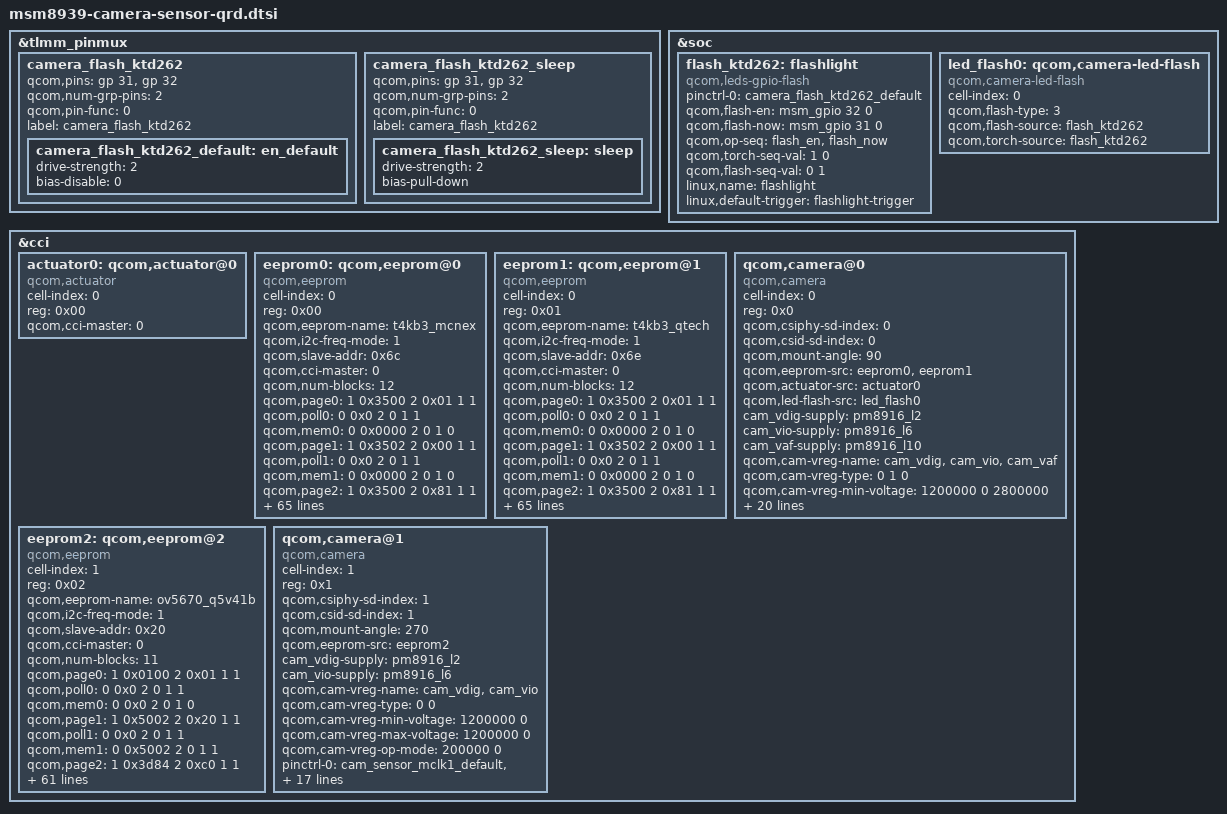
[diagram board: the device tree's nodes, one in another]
/*
 * Copyright (c) 2014, The Linux Foundation. All rights reserved.
 *
 * This program is free software; you can redistribute it and/or modify
 * it under the terms of the GNU General Public License version 2 and
 * only version 2 as published by the Free Software Foundation.
 *
 * This program is distributed in the hope that it will be useful,
 * but WITHOUT ANY WARRANTY; without even the implied warranty of
 * MERCHANTABILITY or FITNESS FOR A PARTICULAR PURPOSE.  See the
 * GNU General Public License for more details.
 */


&tlmm_pinmux {
	camera_flash_ktd262 {
		qcom,pins = <&gp 31>, <&gp 32>;
		qcom,num-grp-pins = <2>;
		qcom,pin-func = <0>;
		label = "camera_flash_ktd262";
		camera_flash_ktd262_default: en_default {
			  drive-strength = <2>;
			  bias-disable = <0>;
		};
	};
	
	camera_flash_ktd262_sleep {
		/* FLSH_RESET,FLASH_EN,FLASH_NOW */
		qcom,pins = <&gp 31>,<&gp 32> ;
		qcom,num-grp-pins = <2>;
		qcom,pin-func = <0>;
		label = "camera_flash_ktd262";
		/* active state */
		camera_flash_ktd262_sleep: sleep {
			drive-strength = <2>; /* 2 MA */
			bias-pull-down; /* PULL DOWN */
		};
	};	
};

&soc {
	flash_ktd262:flashlight {
		compatible = "qcom,leds-gpio-flash";
		status = "okay";
		pinctrl-names = "camera_flash_ktd262_default";
		pinctrl-0 = <&camera_flash_ktd262_default>;
		qcom,flash-en = <&msm_gpio 32 0>;
		qcom,flash-now = <&msm_gpio 31 0>;
		qcom,op-seq = "flash_en", "flash_now";
		qcom,torch-seq-val = <1 0>;
		qcom,flash-seq-val = <0 1>;
		linux,name = "flashlight";
		linux,default-trigger = "flashlight-trigger";
	};

	led_flash0: qcom,camera-led-flash {
		cell-index = <0>;
		compatible = "qcom,camera-led-flash";
		qcom,flash-type = <3>;
		qcom,flash-source = <&flash_ktd262>;
		qcom,torch-source = <&flash_ktd262>;
	};
};

&cci {
	actuator0: qcom,actuator@0 {
		cell-index = <0>;
		reg = <0x00>;
		compatible = "qcom,actuator";
		qcom,cci-master = <0>;
	};

	eeprom0: qcom,eeprom@0 {
		cell-index = <0>;
		reg = <0x00>;
		qcom,eeprom-name = "t4kb3_mcnex";
		compatible = "qcom,eeprom";
		qcom,i2c-freq-mode = <1>;
		qcom,slave-addr = <0x6c>;
		qcom,cci-master = <0>;
		qcom,num-blocks = <12>;

		qcom,page0 = <1 0x3500 2 0x01 1 1>;
		qcom,poll0 = <0 0x0 2 0 1 1>;
		qcom,mem0 = <0 0x0000 2 0 1 0>;

		qcom,page1 = <1 0x3502 2 0x00 1 1>;
		qcom,poll1 = <0 0x0 2 0 1 1>;
		qcom,mem1 = <0 0x0000 2 0 1 0>;

		qcom,page2 = <1 0x3500 2 0x81 1 1>;
		qcom,poll2 = <0 0x0 2 0 1 1>;
		qcom,mem2 = <64 0x3504 2 0 1 0>;

		qcom,page3 = <1 0x3500 2 0x00 1 1>;
		qcom,poll3 = <0 0x0 2 0 1 1>;
		qcom,mem3 = <0 0x0000 2 0 1 0>;

		qcom,page4 = <1 0x3500 2 0x01 1 1>;
		qcom,poll4 = <0 0x0 2 0 1 1>;
		qcom,mem4 = <0 0x0000 2 0 1 0>;

		qcom,page5 = <1 0x3502 2 0x01 1 1>;
		qcom,poll5 = <0 0x0 2 0 1 1>;
		qcom,mem5 = <0 0x0000 2 0 1 0>;

		qcom,page6 = <1 0x3500 2 0x81 1 1>;
		qcom,poll6 = <0 0x0 2 0 1 1>;
		qcom,mem6 = <64 0x3504 2 0 1 0>;

		qcom,page7 = <1 0x3500 2 0x00 1 1>;
		qcom,poll7 = <0 0x0 2 0 1 1>;
		qcom,mem7 = <0 0x0000 2 0 1 0>;

		qcom,page8 = <1 0x3500 2 0x01 1 1>;
		qcom,poll8 = <0 0x0 2 0 1 1>;
		qcom,mem8 = <0 0x0000 2 0 1 0>;
		
		qcom,page9 = <1 0x3502 2 0x02 1 1>;
		qcom,poll9 = <0 0x0 2 0 1 1>;
		qcom,mem9 = <0 0x0000 2 0 1 0>;

		qcom,page10 = <1 0x3500 2 0x81 1 1>;
		qcom,poll10 = <0 0x0 2 0 1 1>;
		qcom,mem10 = <64 0x3504 2 0 1 0>;

		qcom,page11 = <1 0x3500 2 0x00 1 1>;
		qcom,poll11 = <0 0x0 2 0 1 1>;
		qcom,mem11 = <0 0x0000 2 0 1 0>;

		cam_vdig-supply = <&pm8916_l2>;
		cam_vio-supply = <&pm8916_l6>;
		cam_vaf-supply = <&pm8916_l10>;
		qcom,cam-vreg-name = "cam_vdig", "cam_vio","cam_vaf";
		qcom,cam-vreg-type = <0 0 0>;
		qcom,cam-vreg-min-voltage = <1200000 1800000 2800000>;
		qcom,cam-vreg-max-voltage = <1200000 1800000 2800000>;
		qcom,cam-vreg-op-mode = <200000 100000 100000>;
		pinctrl-names = "cam_default", "cam_suspend";
		pinctrl-0 = <&cam_sensor_mclk0_default &cam_sensor_rear_default>;
		pinctrl-1 = <&cam_sensor_mclk0_sleep &cam_sensor_rear_sleep>;
		gpios = <&msm_gpio 26 0>,
			<&msm_gpio 35 0>,
			<&msm_gpio 34 0>,
			<&msm_gpio 2 0>;
		qcom,gpio-reset = <1>;
		qcom,gpio-standby = <2>;
		qcom,gpio-vana = <3>;
		qcom,gpio-req-tbl-num = <0 1 2 3>;
		qcom,gpio-req-tbl-flags = <1 0 0 0>;
		qcom,gpio-req-tbl-label = "CAMIF_MCLK0",
			"MCAM_RESET",
			"MCAM_STANDBY",
			"MCAM_AVDD_EN";
		qcom,cam-power-seq-type = "sensor_vreg", "sensor_gpio", "sensor_gpio", "sensor_vreg",
				"sensor_vreg", "sensor_gpio", "sensor_gpio",
		        "sensor_clk", "sensor_i2c_mux";
		qcom,cam-power-seq-val = "cam_vdig", "sensor_gpio_vana","sensor_gpio_vana","cam_vio",
		                                          "cam_vaf","sensor_gpio_reset", "sensor_gpio_reset", 
		                                           "sensor_cam_mclk", "none";
		qcom,cam-power-seq-cfg-val = <1 0 1 1 1 0 1 24000000 0>;
		qcom,cam-power-seq-delay =    <1 1 1 1 5 5 30 1  0>;
		status = "ok";
		clocks = <&clock_gcc clk_mclk0_clk_src>,
				<&clock_gcc clk_gcc_camss_mclk0_clk>;
		clock-names = "cam_src_clk", "cam_clk";
	};

	eeprom1: qcom,eeprom@1 {
		cell-index = <0>;
		reg = <0x01>;
		qcom,eeprom-name = "t4kb3_qtech";
		compatible = "qcom,eeprom";
		qcom,i2c-freq-mode = <1>;
		qcom,slave-addr = <0x6e>;
		qcom,cci-master = <0>;
		qcom,num-blocks = <12>;

		qcom,page0 = <1 0x3500 2 0x01 1 1>;
		qcom,poll0 = <0 0x0 2 0 1 1>;
		qcom,mem0 = <0 0x0000 2 0 1 0>;

		qcom,page1 = <1 0x3502 2 0x00 1 1>;
		qcom,poll1 = <0 0x0 2 0 1 1>;
		qcom,mem1 = <0 0x0000 2 0 1 0>;

		qcom,page2 = <1 0x3500 2 0x81 1 1>;
		qcom,poll2 = <0 0x0 2 0 1 1>;
		qcom,mem2 = <64 0x3504 2 0 1 0>;

		qcom,page3 = <1 0x3500 2 0x00 1 1>;
		qcom,poll3 = <0 0x0 2 0 1 1>;
		qcom,mem3 = <0 0x0000 2 0 1 0>;

		qcom,page4 = <1 0x3500 2 0x01 1 1>;
		qcom,poll4 = <0 0x0 2 0 1 1>;
		qcom,mem4 = <0 0x0000 2 0 1 0>;

		qcom,page5 = <1 0x3502 2 0x01 1 1>;
		qcom,poll5 = <0 0x0 2 0 1 1>;
		qcom,mem5 = <0 0x0000 2 0 1 0>;

		qcom,page6 = <1 0x3500 2 0x81 1 1>;
		qcom,poll6 = <0 0x0 2 0 1 1>;
		qcom,mem6 = <64 0x3504 2 0 1 0>;

		qcom,page7 = <1 0x3500 2 0x00 1 1>;
		qcom,poll7 = <0 0x0 2 0 1 1>;
		qcom,mem7 = <0 0x0000 2 0 1 0>;

		qcom,page8 = <1 0x3500 2 0x01 1 1>;
		qcom,poll8 = <0 0x0 2 0 1 1>;
		qcom,mem8 = <0 0x0000 2 0 1 0>;
		
		qcom,page9 = <1 0x3502 2 0x02 1 1>;
		qcom,poll9 = <0 0x0 2 0 1 1>;
		qcom,mem9 = <0 0x0000 2 0 1 0>;

		qcom,page10 = <1 0x3500 2 0x81 1 1>;
		qcom,poll10 = <0 0x0 2 0 1 1>;
		qcom,mem10 = <64 0x3504 2 0 1 0>;

		qcom,page11 = <1 0x3500 2 0x00 1 1>;
		qcom,poll11 = <0 0x0 2 0 1 1>;
		qcom,mem11 = <0 0x0000 2 0 1 0>;

		cam_vdig-supply = <&pm8916_l2>;
		cam_vio-supply = <&pm8916_l6>;
		cam_vaf-supply = <&pm8916_l10>;
		qcom,cam-vreg-name = "cam_vdig", "cam_vio","cam_vaf";
		qcom,cam-vreg-type = <0 0 0>;
		qcom,cam-vreg-min-voltage = <1200000 1800000 2800000>;
		qcom,cam-vreg-max-voltage = <1200000 1800000 2800000>;
		qcom,cam-vreg-op-mode = <200000 100000 100000>;
		pinctrl-names = "cam_default", "cam_suspend";
		pinctrl-0 = <&cam_sensor_mclk0_default &cam_sensor_rear_default>;
		pinctrl-1 = <&cam_sensor_mclk0_sleep &cam_sensor_rear_sleep>;
		gpios = <&msm_gpio 26 0>,
			<&msm_gpio 35 0>,
			<&msm_gpio 34 0>,
			<&msm_gpio 2 0>;
		qcom,gpio-reset = <1>;
		qcom,gpio-standby = <2>;
		qcom,gpio-vana = <3>;
		qcom,gpio-req-tbl-num = <0 1 2 3>;
		qcom,gpio-req-tbl-flags = <1 0 0 0>;
		qcom,gpio-req-tbl-label = "CAMIF_MCLK0",
			"MCAM_RESET",
			"MCAM_STANDBY",
			"MCAM_AVDD_EN";
		qcom,cam-power-seq-type = "sensor_vreg", "sensor_gpio", "sensor_gpio", "sensor_vreg",
				"sensor_vreg", "sensor_gpio", "sensor_gpio",
		        "sensor_clk", "sensor_i2c_mux";
		qcom,cam-power-seq-val = "cam_vdig", "sensor_gpio_vana","sensor_gpio_vana","cam_vio",
		                                          "cam_vaf","sensor_gpio_reset", "sensor_gpio_reset", 
		                                           "sensor_cam_mclk", "none";
		qcom,cam-power-seq-cfg-val = <1 0 1 1 1 0 1 24000000 0>;
		qcom,cam-power-seq-delay =    <1 1 1 1 5 5 30 1  0>;
		status = "ok";
		clocks = <&clock_gcc clk_mclk0_clk_src>,
				<&clock_gcc clk_gcc_camss_mclk0_clk>;
		clock-names = "cam_src_clk", "cam_clk";
	};

	qcom,camera@0 {
		cell-index = <0>;
		compatible = "qcom,camera";
		reg = <0x0>;
		qcom,csiphy-sd-index = <0>;
		qcom,csid-sd-index = <0>;
		qcom,mount-angle = <90>;
		qcom,eeprom-src = <&eeprom0 &eeprom1>;
		qcom,actuator-src = <&actuator0>;
		qcom,led-flash-src = <&led_flash0>;
		cam_vdig-supply = <&pm8916_l2>;
		/*cam_vana-supply = <&pm8916_l17>;*/
		cam_vio-supply = <&pm8916_l6>;
		cam_vaf-supply = <&pm8916_l10>;
		qcom,cam-vreg-name = "cam_vdig", "cam_vio","cam_vaf";
		qcom,cam-vreg-type = <0 1 0>;
		qcom,cam-vreg-min-voltage = <1200000 0 2800000>;
		qcom,cam-vreg-max-voltage = <1200000 0 2800000>;
		qcom,cam-vreg-op-mode = <200000 0 100000>;
		pinctrl-names = "cam_default", "cam_suspend";
		pinctrl-0 = <&cam_sensor_mclk0_default &cam_sensor_rear_default>;
		pinctrl-1 = <&cam_sensor_mclk0_sleep &cam_sensor_rear_sleep>;
		gpios = <&msm_gpio 26 0>,
			<&msm_gpio 35 0>,
			<&msm_gpio 34 0>,
			<&msm_gpio 2 0>;
		qcom,gpio-reset = <1>;
		qcom,gpio-standby = <2>;
		qcom,gpio-vana = <3>;
		qcom,gpio-req-tbl-num = <0 1 2 3>;
		qcom,gpio-req-tbl-flags = <1 0 0 0>;
		qcom,gpio-req-tbl-label = "CAMIF_MCLK0",
			"MCAM_RESET",
			"MCAM_STANDBY",
			"MCAM_AVDD_EN";
		qcom,sensor-position = <0>;
		qcom,sensor-mode = <0>;
		qcom,cci-master = <0>;
		status = "ok";
		clocks = <&clock_gcc clk_mclk0_clk_src>,
				<&clock_gcc clk_gcc_camss_mclk0_clk>;
		clock-names = "cam_src_clk", "cam_clk";
	};

	eeprom2: qcom,eeprom@2 {
		cell-index = <1>;
		reg = <0x02>;
		qcom,eeprom-name = "ov5670_q5v41b";
		compatible = "qcom,eeprom";
		qcom,i2c-freq-mode = <1>;
		qcom,slave-addr = <0x20>;
		qcom,cci-master = <0>;
		qcom,num-blocks = <11>;
        	qcom,page0 = <1 0x0100 2 0x01 1 1>;
        	qcom,poll0 = <0 0x0 2 0 1 1>;
        	qcom,mem0 = <0 0x0 2 0 1 0>;
		qcom,page1 = <1 0x5002 2 0x20 1 1>;
		qcom,poll1 = <0 0x0 2 0 1 1>;
		qcom,mem1 = <0 0x5002 2 0 1 1>;
		qcom,page2 = <1 0x3d84 2 0xc0 1 1>;
		qcom,poll2 = <0 0x0 2 0 1 1>;
		qcom,mem2 = <0 0x3d84 2 0 1 0>;
		qcom,page3 = <1 0x3d88 2 0x70 1 1>;
		qcom,poll3 = <0 0x0 2 0 1 1>;
		qcom,mem3 = <0 0x3d88 2 0 1 0>;
		qcom,page4 = <1 0x3d89 2 0x10 1 1>;
		qcom,poll4 = <0 0x0 2 0 1 1>;
		qcom,mem4 = <0 0x3d89 2 0 1 0>;
		qcom,page5 = <1 0x3d8a 2 0x70 1 1>;
		qcom,poll5 = <0 0x0 2 0 1 1>;
		qcom,mem5 = <0 0x3d8a 2 0 1 0>;
		qcom,page6 = <1 0x3d8b 2 0x29 1 1>;
		qcom,poll6 = <0 0x0 2 0 1 1>;
		qcom,mem6 = <0 0x3d8b 2 0 1 0>;
		qcom,page7 = <1 0x3d81 2 0x01 1 5>;
		qcom,poll7 = <0 0x0 2 0 1 1>;
		qcom,mem7 = <0 0x3d81 2 0 1 0>;
		qcom,page8 = <0 0x00 1 0x01 1 1>;
		qcom,poll8 = <0 0x0 2 0 1 1>;
		qcom,mem8= <26 0x7010 2 0 1 1>;//read OTP flag
		qcom,page9 = <1 0x5002 2 0x28 1 1>;
		qcom,poll9 = <0 0x0 2 0 1 1>;
		qcom,mem9= <0 0x7020 2 0 1 0>;
		qcom,page10 = <1 0x0100 2 0x00 1 1>;
		qcom,poll10 = <0 0x0 2 0 1 1>;
		qcom,mem10= <0 0x7020 2 0 1 0>;
		
		cam_vdig-supply = <&pm8916_l2>;
		cam_vio-supply = <&pm8916_l6>;
		qcom,cam-vreg-name = "cam_vdig", "cam_vio";
		qcom,cam-vreg-type = <0 0>;
		qcom,cam-vreg-min-voltage = <1200000 1800000>;
		qcom,cam-vreg-max-voltage = <1200000 1800000>;
		qcom,cam-vreg-op-mode = <150000 150000>;
		pinctrl-names = "cam_default", "cam_suspend";
		pinctrl-0 = <&cam_sensor_mclk1_default &cam_sensor_front_default>;
		pinctrl-1 = <&cam_sensor_mclk1_sleep &cam_sensor_front_sleep>;
		gpios = <&msm_gpio 27 0>,
			<&msm_gpio 28 0>,
			<&msm_gpio 33 0>,
			<&msm_gpio 2  0>;
		qcom,gpio-reset = <1>;
		qcom,gpio-standby = <2>;
		qcom,gpio-vana = <3>;
		qcom,gpio-req-tbl-num = <0 1 2 3>;
		qcom,gpio-req-tbl-flags = <1 0 0 0>;
		qcom,gpio-req-tbl-label = "CAMIF_MCLK1",
			"SCAM_RESET",
			"SCAM_STANDBY",
			"SCAM_AVDD_EN";
		qcom,cam-power-seq-type = "sensor_vreg", "sensor_gpio", "sensor_gpio",
		               "sensor_vreg", "sensor_gpio", "sensor_gpio",
				"sensor_gpio", "sensor_gpio", "sensor_clk", "sensor_i2c_mux";
		qcom,cam-power-seq-val = "cam_vio", "sensor_gpio_vana", "sensor_gpio_vana", 
		              "cam_vdig", "sensor_gpio_standby","sensor_gpio_standby",
 				 "sensor_gpio_reset","sensor_gpio_reset", "sensor_cam_mclk",
		                "none";
		qcom,cam-power-seq-cfg-val = <1 0 1 1 0 1 0 1   24000000 0>;
		qcom,cam-power-seq-delay =   <1  1 1 1 1 5 5 30 10  0>;
		status = "ok";
		clocks = <&clock_gcc clk_mclk1_clk_src>,
				<&clock_gcc clk_gcc_camss_mclk1_clk>;
		clock-names = "cam_src_clk", "cam_clk";
	};

	qcom,camera@1 {
		cell-index = <1>;
		compatible = "qcom,camera";
		reg = <0x1>;
		qcom,csiphy-sd-index = <1>;
		qcom,csid-sd-index = <1>;
		qcom,mount-angle = <270>;
		qcom,eeprom-src = <&eeprom2>;
		cam_vdig-supply = <&pm8916_l2>;
		/*cam_vana-supply = <&pm8916_l17>;*/
		cam_vio-supply = <&pm8916_l6>;
		qcom,cam-vreg-name = "cam_vdig", "cam_vio";
		qcom,cam-vreg-type = <0 0>;
		qcom,cam-vreg-min-voltage = <1200000 0>;
		qcom,cam-vreg-max-voltage = <1200000 0>;
		qcom,cam-vreg-op-mode = <200000 0>;
		pinctrl-names = "cam_default", "cam_suspend";
		pinctrl-0 = <&cam_sensor_mclk1_default &cam_sensor_front_default>;
		pinctrl-1 = <&cam_sensor_mclk1_sleep &cam_sensor_front_sleep>;
		gpios = <&msm_gpio 27 0>,
			<&msm_gpio 28 0>,
			<&msm_gpio 33 0>,
			<&msm_gpio 2 0>;
		qcom,gpio-reset = <1>;
		qcom,gpio-standby = <2>;
		qcom,gpio-vana = <3>;
		qcom,gpio-req-tbl-num = <0 1 2 3>;
		qcom,gpio-req-tbl-flags = <1 0 0 0>;
		qcom,gpio-req-tbl-label = "CAMIF_MCLK1",
			"SCAM_RESET",
			"SCAM_STANDBY",
			"SCAM_AVDD_EN";
		qcom,sensor-position = <1>;
		qcom,sensor-mode = <0>;
		qcom,cci-master = <0>;
		status = "ok";
		clocks = <&clock_gcc clk_mclk1_clk_src>,
				<&clock_gcc clk_gcc_camss_mclk1_clk>;
		clock-names = "cam_src_clk", "cam_clk";
	};
};
